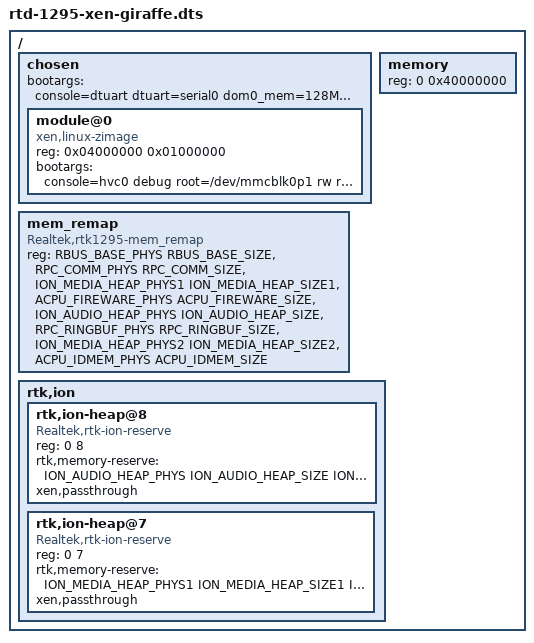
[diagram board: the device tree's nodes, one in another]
/dts-v1/;
#include "../../../../../include/soc/realtek/memory.h"

/memreserve/ SYS_BOOTCODE_MEMBASE       SYS_BOOTCODE_MEMSIZE        ; /* 0x00000000 ~ 0x0002ffff */
/memreserve/ RPC_COMM_PHYS              RPC_COMM_SIZE               ; /* 0x0001f000 ~ 0x0001ffff */
/memreserve/ RPC_RINGBUF_PHYS           RPC_RINGBUF_SIZE            ; /* 0x01ffe000 ~ 0x02001fff */
/memreserve/ ION_AUDIO_HEAP_PHYS        ION_AUDIO_HEAP_SIZE         ; /* 0x02600000 ~ 0x031fffff */
/memreserve/ ION_MEDIA_HEAP_PHYS1       ION_MEDIA_HEAP_SIZE1        ; /* 0x03200000 ~ 0x0e9fffff */
/memreserve/ ACPU_IDMEM_PHYS            ACPU_IDMEM_SIZE             ; /* 0x10000000 ~ 0x10013fff */
/memreserve/ ION_MEDIA_HEAP_PHYS2       ION_MEDIA_HEAP_SIZE2        ; /* 0x11000000 ~ 0x181fffff */

#include "rtd-1295-xen.dtsi"
#include "rtd-129x-dvfs.dtsi"
#include "rtd-1295-xen-giraffe-common.dtsi"

/ {

    chosen {
        #address-cells = <0x1>;
        #size-cells = <0x1>;

        bootargs = "console=dtuart dtuart=serial0 dom0_mem=128MB dom0_max_vcpus=4";

        module@0 {
            compatible = "xen,linux-zimage", "xen,multiboot-module";
            reg = <0x04000000 0x01000000>;
            bootargs = "console=hvc0 debug root=/dev/mmcblk0p1 rw rootwait swiotlb=8192";
            /*bootargs = "earlycon=uart8250,mmio32,0x98007800 console=hvc0 debug root=/dev/mmcblk0p1 rw rootwait swiotlb=16384";*/
        };
    };

    memory {
        device_type = "memory";
        reg = <0 0x40000000>;   /* 1024 MB */
    };

    mem_remap {
        compatible = "Realtek,rtk1295-mem_remap";
        reg = <RBUS_BASE_PHYS RBUS_BASE_SIZE>,
              <RPC_COMM_PHYS RPC_COMM_SIZE>,
              <ION_MEDIA_HEAP_PHYS1 ION_MEDIA_HEAP_SIZE1>,
              <ACPU_FIREWARE_PHYS ACPU_FIREWARE_SIZE>,
              <ION_AUDIO_HEAP_PHYS ION_AUDIO_HEAP_SIZE>,
              <RPC_RINGBUF_PHYS RPC_RINGBUF_SIZE>,
              <ION_MEDIA_HEAP_PHYS2 ION_MEDIA_HEAP_SIZE2>,
              <ACPU_IDMEM_PHYS ACPU_IDMEM_SIZE>;
    };

    rtk,ion {
        rtk,ion-heap@8 {    /* Audio */
            compatible = "Realtek,rtk-ion-reserve";
            reg = <0 8>;
            rtk,memory-reserve = <
                ION_AUDIO_HEAP_PHYS ION_AUDIO_HEAP_SIZE ION_AUDIO_HEAP_FLAG
                >;
            xen,passthrough;
        };
        rtk,ion-heap@7 {    /* TYPE_MEDIA */
            compatible = "Realtek,rtk-ion-reserve";
            reg = <0 7>;
            rtk,memory-reserve = <
                ION_MEDIA_HEAP_PHYS1 ION_MEDIA_HEAP_SIZE1 ION_MEDIA_HEAP_FLAG1
                ION_MEDIA_HEAP_PHYS2 ION_MEDIA_HEAP_SIZE2 ION_MEDIA_HEAP_FLAG2
                >;
            xen,passthrough;
        };
    };
};
